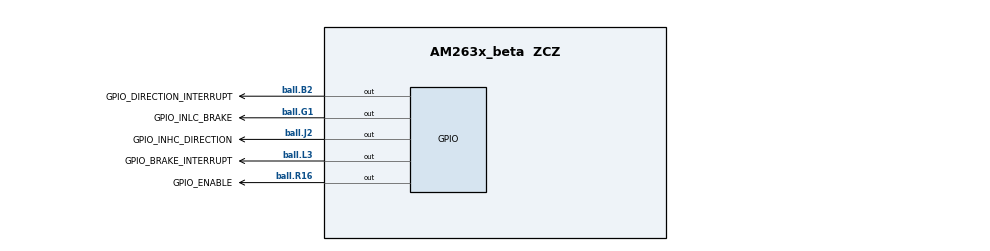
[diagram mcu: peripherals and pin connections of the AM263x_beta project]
/**
 * @cliArgs --device "AM263x_beta" --package "ZCZ" --part "AM263x" --context "r5fss0-0" --product "MCU_PLUS_SDK_AM263x@08.03.01"
 * @versions {"tool":"1.15.0+2826"}
 */

/**
 * Import the modules used in this configuration.
 */
const adc            = scripting.addModule("/drivers/adc/adc", {}, false);
const adc1           = adc.addInstance();
const epwm           = scripting.addModule("/drivers/epwm/epwm", {}, false);
const epwm1          = epwm.addInstance();
const eqep           = scripting.addModule("/drivers/eqep/eqep", {}, false);
const eqep1          = eqep.addInstance();
const gpio           = scripting.addModule("/drivers/gpio/gpio", {}, false);
const gpio1          = gpio.addInstance();
const gpio2          = gpio.addInstance();
const gpio3          = gpio.addInstance();
const gpio4          = gpio.addInstance();
const gpio5          = gpio.addInstance();
const debug_log      = scripting.addModule("/kernel/dpl/debug_log");
const mpu_armv7      = scripting.addModule("/kernel/dpl/mpu_armv7", {}, false);
const mpu_armv71     = mpu_armv7.addInstance();
const mpu_armv72     = mpu_armv7.addInstance();
const mpu_armv73     = mpu_armv7.addInstance();
const mpu_armv74     = mpu_armv7.addInstance();
const timer          = scripting.addModule("/kernel/dpl/timer", {}, false);
const timer1         = timer.addInstance();
const gpio_int_xbar  = scripting.addModule("/xbar/gpio_int_xbar/gpio_int_xbar", {}, false);
const gpio_int_xbar1 = gpio_int_xbar.addInstance();
const gpio_int_xbar2 = gpio_int_xbar.addInstance();
const int_xbar       = scripting.addModule("/xbar/int_xbar/int_xbar", {}, false);
const int_xbar1      = int_xbar.addInstance();

/**
 * Write custom configuration values to the imported modules.
 */
adc1.adcClockPrescaler  = "ADC_CLK_DIV_4_0";
adc1.enableConverter    = true;
adc1.interruptPulseMode = "ADC_PULSE_END_OF_CONV";
adc1.enableInterrupt1   = true;
adc1.soc0SampleWindow   = 16;
adc1.soc1SampleWindow   = 16;
adc1.soc2SampleWindow   = 16;
adc1.soc3SampleWindow   = 16;
adc1.soc4SampleWindow   = 16;
adc1.soc5SampleWindow   = 16;
adc1.soc6SampleWindow   = 16;
adc1.soc7SampleWindow   = 16;
adc1.soc8SampleWindow   = 16;
adc1.soc9SampleWindow   = 16;
adc1.soc10SampleWindow  = 16;
adc1.soc11SampleWindow  = 16;
adc1.soc12SampleWindow  = 16;
adc1.soc13SampleWindow  = 16;
adc1.soc14SampleWindow  = 16;
adc1.soc15SampleWindow  = 16;
adc1.soc3Channel        = "ADC_CH_ADCIN3";
adc1.$name              = "CONFIG_ADC3";
adc1.ADC.$assign        = "ADC3";
adc1.ADC.AIN1.$used     = false;
adc1.ADC.AIN2.$used     = false;
adc1.ADC.AIN3.$used     = false;
adc1.ADC.AIN4.$used     = false;
adc1.ADC.AIN5.$used     = false;

epwm1.epwmTimebase_emulationMode                                 = "EPWM_EMULATION_FREE_RUN";
epwm1.epwmTimebase_counterMode                                   = "EPWM_COUNTER_MODE_UP_DOWN";
epwm1.epwmTimebase_syncOutPulseMode                              = ["EPWM_SYNC_OUT_PULSE_ON_ALL"];
epwm1.epwmActionQualifier_EPWM_AQ_OUTPUT_A_ON_TIMEBASE_UP_CMPA   = "EPWM_AQ_OUTPUT_HIGH";
epwm1.epwmActionQualifier_EPWM_AQ_OUTPUT_A_ON_TIMEBASE_DOWN_CMPA = "EPWM_AQ_OUTPUT_LOW";
epwm1.epwmActionQualifier_EPWM_AQ_OUTPUT_B_ON_TIMEBASE_UP_CMPB   = "EPWM_AQ_OUTPUT_HIGH";
epwm1.epwmActionQualifier_EPWM_AQ_OUTPUT_B_ON_TIMEBASE_DOWN_CMPB = "EPWM_AQ_OUTPUT_LOW";
epwm1.epwmEventTrigger_enableInterrupt                           = true;
epwm1.epwmEventTrigger_interruptEventCount                       = "1";
epwm1.epwmTimebase_clockDiv                                      = "EPWM_CLOCK_DIVIDER_4";
epwm1.epwmTimebase_period                                        = 25000;
epwm1.$name                                                      = "PWM13_B_INHA";
epwm1.epwmCounterCompare_cmpB                                    = 25000;
epwm1.EPWM.$assign                                               = "EPWM13";
epwm1.EPWM.A.$used                                               = false;

eqep1.$name                = "CONFIG_EQEP0";
eqep1.eqepOperationMode    = "EQEP_CONFIG_UP_COUNT";
eqep1.positionCounterMax   = 116000;
eqep1.enableModule         = true;
eqep1.positionCounterMode  = "EQEP_POSITION_RESET_MAX_POS";
eqep1.latchPositionCounter = "EQEP_LATCH_UNIT_TIME_OUT";
eqep1.swPositionInit       = true;
eqep1.captureConfig        = true;
eqep1.capPrescale          = "EQEP_CAPTURE_CLK_DIV_128";
eqep1.evntPrescale         = "EQEP_UNIT_POS_EVNT_DIV_8";
eqep1.enableCapture        = true;
eqep1.enableUnitTimer      = true;
eqep1.emulationMode        = "EQEP_EMULATIONMODE_RUNFREE";
eqep1.selectSourceA        = "EQEP_SOURCE_DEVICE_PIN";
eqep1.selectSourceB        = "EQEP_SOURCE_DEVICE_PIN";
eqep1.eqepResolution       = "EQEP_CONFIG_1X_RESOLUTION";
eqep1.unitTimerPeriod      = 2000000;
eqep1.enableCompare        = true;
eqep1.compareConfig        = true;
eqep1.enableInterrupt      = true;
eqep1.EQEP.A.$assign       = "ball.B14";

gpio1.$name                = "GPIO_ENABLE";
gpio1.pinDir               = "OUTPUT";
gpio1.GPIO.gpioPin.$assign = "ball.R16";

gpio2.$name                = "GPIO_INHC_DIRECTION";
gpio2.pinDir               = "OUTPUT";
gpio2.GPIO.gpioPin.$assign = "ball.J2";

gpio3.$name                = "GPIO_INLC_BRAKE";
gpio3.pinDir               = "OUTPUT";
gpio3.GPIO.gpioPin.$assign = "ball.G1";

gpio4.$name                = "GPIO_DIRECTION_INTERRUPT";
gpio4.trigType             = "BOTH_EDGE";
gpio4.GPIO.gpioPin.$assign = "ball.B2";

gpio5.$name                = "GPIO_BRAKE_INTERRUPT";
gpio5.trigType             = "BOTH_EDGE";
gpio5.GPIO.gpioPin.$assign = "ball.L3";

debug_log.enableUartLog            = true;
debug_log.uartLog.$name            = "CONFIG_UART0";
debug_log.uartLog.UART.$assign     = "UART0";
debug_log.uartLog.UART.RXD.$assign = "ball.A7";
debug_log.uartLog.UART.TXD.$assign = "ball.A6";

mpu_armv71.$name             = "CONFIG_MPU_REGION0";
mpu_armv71.size              = 31;
mpu_armv71.attributes        = "Device";
mpu_armv71.accessPermissions = "Supervisor RD+WR, User RD";
mpu_armv71.allowExecute      = false;

mpu_armv72.$name             = "CONFIG_MPU_REGION1";
mpu_armv72.size              = 15;
mpu_armv72.accessPermissions = "Supervisor RD+WR, User RD";

mpu_armv73.$name             = "CONFIG_MPU_REGION2";
mpu_armv73.baseAddr          = 0x80000;
mpu_armv73.size              = 15;
mpu_armv73.accessPermissions = "Supervisor RD+WR, User RD";

mpu_armv74.$name             = "CONFIG_MPU_REGION3";
mpu_armv74.accessPermissions = "Supervisor RD+WR, User RD";
mpu_armv74.baseAddr          = 0x70000000;
mpu_armv74.size              = 21;

timer1.$name         = "CONFIG_TIMER0";
timer1.timerCallback = "App_timerIntrISR";
timer1.usecPerTick   = 10;
timer1.intrPriority  = 1;

gpio_int_xbar1.$name      = "CONFIG_GPIO_INT_XBAR0";
gpio_int_xbar1.instance   = "GPIO_INT_XBAR_VIM_MODULE0_0";
gpio_int_xbar1.xbarOutput = "GPIO_INT_XBAR_GPIO_0_BANK_INTR_2";

gpio_int_xbar2.$name      = "CONFIG_GPIO_INT_XBAR1";
gpio_int_xbar2.instance   = "GPIO_INT_XBAR_VIM_MODULE0_1";
gpio_int_xbar2.xbarOutput = "GPIO_INT_XBAR_GPIO_0_BANK_INTR_4";

int_xbar1.$name      = "CONFIG_INT_XBAR0";
int_xbar1.xbarOutput = ["EPWM13_INT"];

/**
 * Pinmux solution for unlocked pins/peripherals. This ensures that minor changes to the automatic solver in a future
 * version of the tool will not impact the pinmux you originally saw.  These lines can be completely deleted in order to
 * re-solve from scratch.
 */
adc1.ADC.AIN0.$suggestSolution     = "ball.U7";
epwm1.EPWM.B.$suggestSolution      = "ball.K3";
eqep1.EQEP.$suggestSolution        = "EQEP0";
eqep1.EQEP.B.$suggestSolution      = "ball.A14";
eqep1.EQEP.STROBE.$suggestSolution = "ball.C12";
eqep1.EQEP.INDEX.$suggestSolution  = "ball.D11";
gpio1.GPIO.$suggestSolution        = "GPIO0";
gpio2.GPIO.$suggestSolution        = "GPIO0";
gpio3.GPIO.$suggestSolution        = "GPIO0";
gpio4.GPIO.$suggestSolution        = "GPIO0";
gpio5.GPIO.$suggestSolution        = "GPIO0";
timer1.RTI.$suggestSolution        = "RTI1";
